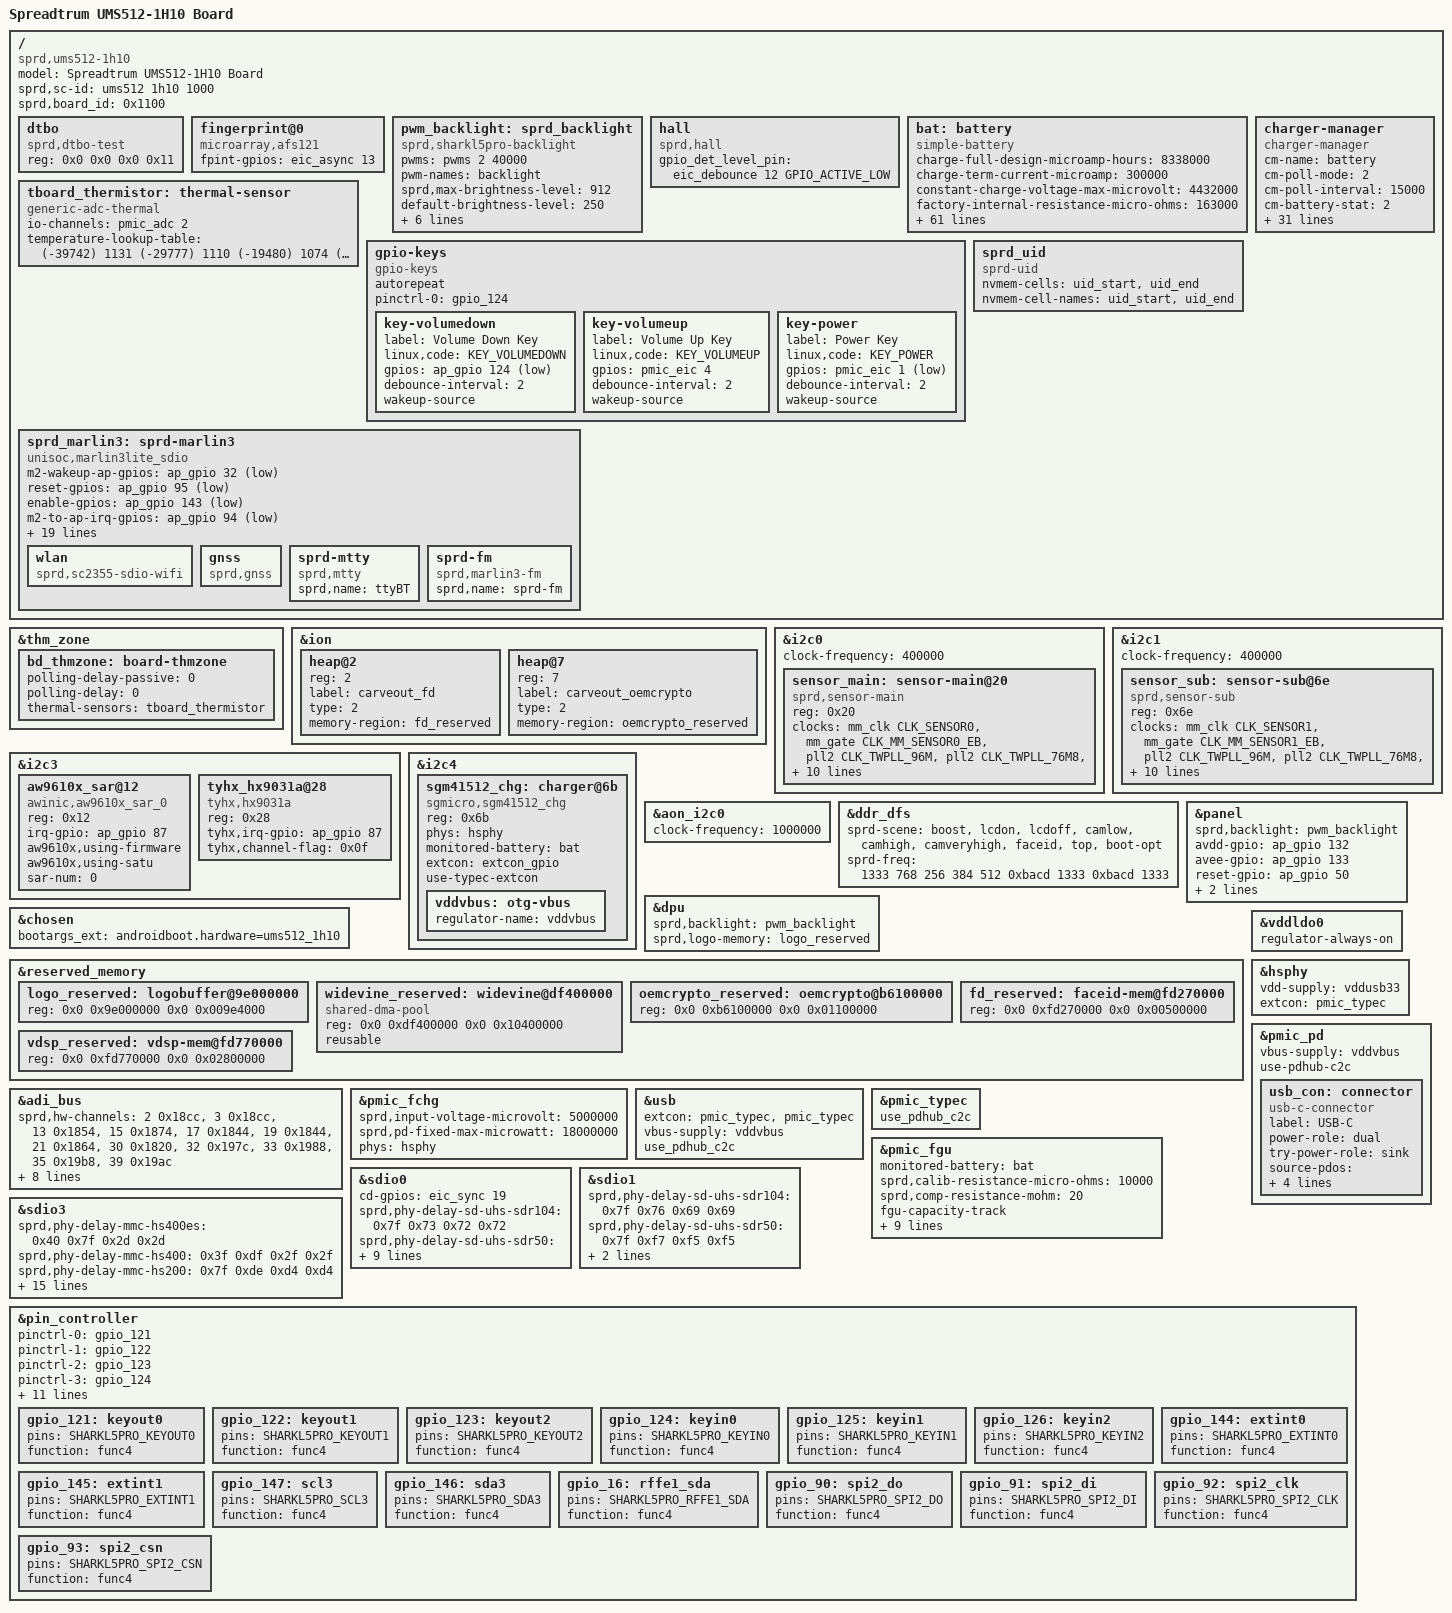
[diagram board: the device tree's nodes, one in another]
/dts-v1/;
/plugin/;

#include <dt-bindings/clock/sprd,ums512-clk.h>
#include <dt-bindings/input/input.h>
#include <dt-bindings/gpio/gpio.h>
#include <dt-bindings/mfd/sprd,sc2730-regs.h>
#include <dt-bindings/mfd/sprd,sc2730-mask.h>

#include "lcd/lcd_dijing_2A4N3_truly_mipi_fhd.dtsi"
#include "lcd/lcd_dijing_nt36523_truly_mipi_fhd.dtsi"
#include "lcd/lcd_lianchuang_mipi_fhd.dtsi"

#include "tp/novatek-nt36xxx-spi.dtsi"
#include <dt-bindings/usb/pd.h>

/ {
	model = "Spreadtrum UMS512-1H10 Board";

	compatible = "sprd,ums512-1h10", "sprd,ums512";

	sprd,sc-id = "ums512 1h10 1000";

	sprd,board_id = <0x1100>; //XX00:base board,XX00~XXFF:customize board

	fragment {
		target-path = "/";
		__overlay__ {
			#address-cells = <2>;
			#size-cells = <2>;

			dtbo: dtbo {
				compatible = "sprd,dtbo-test";
				reg = <0x0 0x0 0x0 0x11>;
			};

			fingerprint@0 {
				compatible = "microarray,afs121";
				fpint-gpios = <&eic_async 13 0>;
			};

			pwm_backlight: sprd_backlight {
				compatible = "sprd,sharkl5pro-backlight";
				pwms = <&pwms 2 40000>;
				pwm-names = "backlight";
				sprd,max-brightness-level = <912>;
				default-brightness-level = <250>;
			//	sprd,brightness-scale = <1023>;
				brightness-levels = <
						         3  11  11  11  11  12
					 12  12  12  13  13  13  14  14  15  15         //15
					 16  17  18  19  20  21  22  23  24  25        //25
					 26  27  28  29  30  31  32  33  34  35        //35
					 36  37  38  39  40  41  42  43  44  45        //45
					 46  47  48  49  52  55  58  61  64  67        //55
					 70  73  76  79  82  85  88  91  94  97         //65
					100 103 106 109 112 116 119 121 124 126        //75
					128 131 133 135 138 140 142 145 147 149			//85
					152 155 158 161 164 167 170 174 177 181			//95		 
					184 187 190 193 196 199 202 205 208 211		  // 105
					214 217 220 223 226 229 232 235 238 241		  // 115
					244 247 250 253 256 259 263 267 270 274		  // 125
					277 280 284 287 290 293 297 300 304 307		  // 135
					310 314 317 320 323 327 330 334 337 340       // 145
					344 348 352 356 360 364 363 367 371 375       // 155
					379 383 387 391 395 399 403 407 411 415	      // 165
					420 424 428 431 434 438 442 447 452 457		  // 175
					460 462 465 470 475 480 485 490 492 497       // 185
					502 507 512 517 522 527 532 537 541 547       // 195
					553 560 566 572 578 584 590 596 602 608		  // 205
					614 620 626 633 640 647 654 661 668 675       // 215
					680 685 690 705 714 724 730 742 750 756       // 225
					763 770 776 782 788 794 801 808 814 820       // 235
					826 834 841 848 854 860 867 870 874 877       // 245
					881 884 888 891 895 898 902 905 909 912
				>;
				brightness-levels-djn = <
						         0   5   5   6   6   6
					  7   8   8   9   9  10  10  11  12  13         //15
					 14  14  15  15  16  17  18  19  20  20        //25
					 21  21  22  22  23  24  24  25  25  26        //35
					 27  28  29  30  31  32  33  34  35  36        //45
					 38  40  42  43  45  47  48  49  50  52        //55
					 55  57  60  62  64  67  69  72  74  76         //65
					 78  80  82  84  86  88  90  92  94  97        //75
					 99 101 103 105 107 110 112 114 116 119			//85
					121 124 126 129 131 134 136 139 142 145			//95		 
					147 150 152 155 157 160 162 165 167 170		  // 105
					172 175 177 180 182 184 186 189 191 193		  // 115
					195 198 200 203 205 208 211 214 217 220		  // 125
					223 226 229 232 235 238 241 243 245 247		  // 135
					250 252 255 258 261 264 267 270 272 274       // 145
					277 280 283 286 289 292 295 298 301 304       // 155
					307 310 314 317 320 324 327 330 334 337	      // 165
					340 343 347 350 354 357 360 364 367 371		  // 175
					373 376 378 381 383 386 389 391 393 395       // 185
					399 404 408 413 417 422 427 432 437 442       // 195
					446 451 455 460 464 469 475 480 485 490		  // 205
					495 501 506 511 516 521 526 531 536 541       // 215
					548 555 563 570 577 585 592 599 606 614       // 225
					618 623 627 633 638 642 647 651 656 661       // 235
					665 670 677 682 687 693 698 704 709 714       // 245
					716 718 720 721 722 724 725 727 728 730
				>;
				brightness-levels-boe = <
						          0   5   6   6   7   7
					  8   9  10  10  11  11  12  12  13  13         //15
					 14  15  16  17  18  19  20  21  22  23        //25
					 24  25  26  27  28  29  30  31  32  33        //35
					 34  35  36  37  38  39  40  41  42  43        //45
					 44  45  46  47  48  49  50  51  52  53        //55
					 56  59  62  65  68  71  74  77  80  82         //65
					 85  88  90  93  96  98 101 104 106 109        //75
					111 113 115 117 118 120 122 124 126 128			//85
					131 134 137 140 141 144 147 150 152 155			//95		 
					158 160 163 166 169 172 175 177 179 181		  // 105
					184 187 190 193 196 199 202 204 206 208		  // 115
					211 214 217 220 223 226 229 221 223 235		  // 125
					238 241 244 247 250 254 257 260 263 267		  // 135
					270 273 276 279 282 285 288 291 292 293       // 145
					297 300 303 307 310 313 317 320 324 327       // 155
					330 333 337 340 343 347 350 353 357 360	      // 165
					364 368 371 374 378 381 384 388 392 395		  // 175
					399 403 407 410 414 418 422 426 430 434       // 185
					438 442 446 450 454 458 462 466 470 475       // 195
					480 486 491 497 502 508 513 519 526 532		  // 205
					538 544 550 556 562 568 574 580 585 590       // 215
					597 604 611 618 625 632 639 646 653 661       // 225
					666 671 677 682 687 692 698 703 708 714       // 235
					719 724 729 734 739 744 749 753 758 763       // 245
					765 768 770 773 775 778 780 782 785 788
				>;
			};

			hall {
				compatible = "sprd,hall";
				gpio_det_level_pin = <&eic_debounce 12 GPIO_ACTIVE_LOW>;
				status = "okay";
			};
			
			bat: battery {
				compatible = "simple-battery";
				charge-full-design-microamp-hours = <8338000>;
				charge-term-current-microamp = <300000>;
				constant-charge-voltage-max-microvolt = <4432000>;
				factory-internal-resistance-micro-ohms = <163000>;
				voltage-min-design-microvolt = <3450000>;
				fullbatt-voltage = <4340000>;
				fullbatt-current = <300000>;
				first-fullbatt-current = <150000>;
				fullbatt-track-end-vol = <4345000>;
				fullbatt-track-end-cur = <130000>;
				first-calib-voltage = <3630000>;
				first-calib-capacity = <50>;
				batt-ovp-threshold-microvolt = <4800000>;

				ocv-capacity-celsius = <20>;
				ocv-capacity-table-0 = <4353000 100>, <4288000 95>, <4229000 90>,
							<4172000 85>, <4118000 80>, <4066000 75>,
							<4014000 70>, <3973000 65>, <3927000 60>,
							<3872000 55>, <3841000 50>, <3818000 45>,
							<3799000 40>, <3783000 35>, <3770000 30>,
							<3753000 25>, <3736000 20>, <3712000 15>,
							<3685000 10>, <3668000 5>, <3400000 0>;
				voltage-temp-table = <1134000 800>, <1038000 840>, <943000 880>, <854000 920>, 
							  <771000 960>, <686000 1000>, <614000 1040>, <545000 1080>,
							  <486000 1120>, <429000 1160>, <387000 1200>, <338000 1240>,
							  <295000 1280>, <263000 1320>, <231000 1360>, <203000 1400>, 
							  <179000 1440>, <157000 1480>, <139000 1520>, <125000 1560>, 
							  <111000 1600>, <96000 1650>;
				capacity-temp-table = <45 100>, <25 100>, <10 94>, <0 94>, <(-10) 75>, <(-20) 65>;
				resistance-temp-table = <45 77>, <25 100>, <10 246>, <0 469>, <(-10) 692>, <(-20) 823>;



				charge-sdp-current-microamp = <500000 500000>;
				charge-dcp-current-microamp = <2000000 2010000>;
				charge-cdp-current-microamp = <2000000 2010000>;
				charge-unknown-current-microamp = <500000 500000>;

				cap-calib-energy-density-ocv-table = <3350000 3800000>, <4150000 4350000>;
				cap-track-energy-density-ocv-table = <3400000 3722000>;
				charge-fchg-current-microamp = <3000000 3200000>;
				dcp-jeita-temp-table = <1000 1010 0 4432000>, <1100 1110 1620000 4432000>,
					<1450 1400 2000000 4432000>, <1550 1500 2000000 4432000>;
				sdp-jeita-temp-table = <1000 1010 500000 4432000>, <1100 1110 500000 4432000>,
					<1450 1400 500000 4432000>, <1550 1500 500000 4432000>;
				cdp-jeita-temp-table = <1000 1010 1000000 4432000>, <1100 1110 1620000 4432000>,
					<1450 1400 2000000 4432000>, <1550 1500 2000000 4432000>;
				unknown-jeita-temp-table = <1000 1010 0 4432000>, <1100 1110 500000 4432000>,
					<1450 1400 500000 4432000>, <1550 1500 500000 4432000>;
                fchg-jeita-temp-table = <1000 1010 0 4432000>, <1100 1110 1620000 4432000>,
					<1450 1400 3000000 4432000>, <1550 1500 3000000 4432000>;                       
				force-jeita-status = <2>;
			};

			charger-manager {
				compatible = "charger-manager";
				cm-name = "battery";
				cm-poll-mode = <2>;
				cm-poll-interval = <15000>;
				cm-battery-stat = <2>;

				cm-fullbatt-vchkdrop-ms = <30000>;
				cm-fullbatt-vchkdrop-volt = <60000>;
				cm-fullbatt-capacity = <100>;

				cm-num-chargers = <1>;
				cm-num-fast-chargers = <1>;
				cm-chargers = "sgm41512_charger";
				sprd,support-fchg;
				cm-charge-pumps = "sc27xx_fast_charger";
				cm-fuel-gauge = "sc27xx-fgu";

				/* in deci centigrade */
				cm-battery-cold = <0>;
				cm-battery-cold-in-minus;
				cm-battery-hot = <800>;
				cm-battery-temp-diff = <100>;

				/* Allow charging for 6hr */
				cm-charging-max = <43200000>;
				/* recovery charging after stop charging 45min */
				cm-discharging-max = <2700000>;

				/* the interval to feed charger watchdog */
				cm-wdt-interval = <60>;

				/* drop voltage in microVolts to allow shutdown */
				cm-shutdown-voltage = <3400000>;

				/* when 99% of the time is exceeded, it will be forced to 100% */
				cm-tickle-time-out = <1500>;

				/* how much time to allow capacity change */
				cm-one-cap-time = <30>;
				cm-thermal-zone = "board-thmzone";
				/* when the safe charging voltage is exceeded, stop charging */
				cm-charge-voltage-max = <6500000>;
				/* drop voltage in microVolts to restart charging */
				cm-charge-voltage-drop = <700000>;
				/* when the safe charging voltage is exceeded, stop charging */
				cm-fast-charge-voltage-max = <10500000>;
				/* drop voltage in microVolts to restart charging */
				cm-fast-charge-voltage-drop = <700000>;

				monitored-battery = <&bat>;

				cm-cap-remap-table = <1 4 3>, <4 20 1>, <98 99 1>, <99 100 1>;

				phys = <&hsphy>;
				
				extcon = <&pmic_typec>, <&pmic_pd>;
				pd-extcon-enable;
				use-typec-extcon;

			};
			tboard_thermistor:thermal-sensor {
				compatible = "generic-adc-thermal";
				#thermal-sensor-cells = <0>;
				io-channels = <&pmic_adc 2>;
				io-channel-names = "sensor-channel";
				temperature-lookup-table = <    (-39742) 1131
								(-29777) 1110
								(-19480) 1074
								(-4679) 983
								10110 838
								24805 654
								44922 413
								54903 316
								64895 238
								74884 178
								84883 133
								94883 100
								104880 75
								114889 57
								124872 43 >;
			};
			gpio-keys {
				compatible = "gpio-keys";
				autorepeat;
				pinctrl-names = "gpio_124";
				pinctrl-0 = <&gpio_124>;
				key-volumedown {
					label = "Volume Down Key";
					linux,code = <KEY_VOLUMEDOWN>;
					gpios = <&ap_gpio 124 GPIO_ACTIVE_LOW>;
					debounce-interval = <2>;
					wakeup-source;
				};

				key-volumeup {
					label = "Volume Up Key";
					linux,code = <KEY_VOLUMEUP>;
					gpios = <&pmic_eic 4 GPIO_ACTIVE_HIGH>;
					debounce-interval = <2>;
					wakeup-source;
				};

				key-power {
					label = "Power Key";
					linux,code = <KEY_POWER>;
					gpios = <&pmic_eic 1 GPIO_ACTIVE_LOW>;
					debounce-interval = <2>;
					wakeup-source;
				};
			};

			sprd_uid {
				compatible = "sprd-uid";
				nvmem-cells = <&uid_start>, <&uid_end>;
				nvmem-cell-names = "uid_start", "uid_end";
			};

			sprd_marlin3: sprd-marlin3 {
				compatible = "unisoc,marlin3lite_sdio";
				m2-wakeup-ap-gpios = <&ap_gpio 32 GPIO_ACTIVE_LOW>;
				reset-gpios = <&ap_gpio 95 GPIO_ACTIVE_LOW>;
				enable-gpios = <&ap_gpio 143 GPIO_ACTIVE_LOW>;
				m2-to-ap-irq-gpios = <&ap_gpio 94 GPIO_ACTIVE_LOW>;
				avdd12-supply = <&vddwcn>;
				avdd33-supply = <&vddwifipa>;
				dcxo18-supply = <&vddsim2>;

				clock-names = "clk_32k","source","enable";
				clocks = <&aon_clk CLK_AUX0>,
					 <&ext_32k>,
					 <&aonapb_gate CLK_AUX0_EB>;

				extcon = <&sdio1>;
				sdhci-name = <&sdio1>;

				sprd,btwf-file-name = "/dev/block/platform/soc/soc:ap-apb/71400000.sdio/by-name/wcnmodem";
				sprd,gnss-file-name = "/vendor/firmware/gnssmodem.bin";
				adma-tx;
				adma-rx;
				/*
				 * bound parameter:
				 * [0]:addr offset, [1]:mask, [2]:unboundval, [3]:boundval
				 */
				avdd12-parent-bound-chip = <REG_ANA_SLP_DCDC_PD_CTRL MASK_ANA_SLP_DCDCGEN1_PD_EN 0x0 MASK_ANA_SLP_DCDCGEN1_PD_EN>;
				avdd12-bound-wbreq = <REG_ANA_LDO_XTL_EN10 MASK_ANA_LDO_VDDWCN_EXT_XTL3_EN 0x0 MASK_ANA_LDO_VDDWCN_EXT_XTL3_EN>;
				avdd33-bound-wbreq = <REG_ANA_LDO_XTL_EN11 MASK_ANA_LDO_VDDWIFIPA_EXT_XTL3_EN 0x0 MASK_ANA_LDO_VDDWIFIPA_EXT_XTL3_EN>;

				wlan {
					compatible = "sprd,sc2355-sdio-wifi";
				};

				gnss {
					compatible = "sprd,gnss";
				};

				sprd-mtty {
					compatible = "sprd,mtty";
					sprd,name = "ttyBT";
				};

				sprd-fm {
					compatible = "sprd,marlin3-fm";
					sprd,name = "sprd-fm";
				};
			};
		};
	};
};

&thm_zone {
	bd_thmzone: board-thmzone {
		polling-delay-passive = <0>;
		polling-delay = <0>;
		thermal-sensors = <&tboard_thermistor>;
	};
};

&ion {
	#address-cells = <1>;
	#size-cells = <0>;

	heap@2 {
		reg = <2>;
		label = "carveout_fd";
		type = <2>;
		memory-region = <&fd_reserved>;
	};

	heap@7 {
		reg = <7>;
		label = "carveout_oemcrypto";
		type = <2>;
		memory-region = <&oemcrypto_reserved>;
	};
};

&i2c0 {
	#address-cells = <1>;
	#size-cells = <0>;

	status = "okay";
	clock-frequency = <400000>;

	sensor_main: sensor-main@20 {
		compatible = "sprd,sensor-main";
		reg = <0x20>;
		clock-names = "clk_src","sensor_eb",
			"clk_96m","clk_76m8",
			"clk_48m","clk_26m";
		clocks = <&mm_clk CLK_SENSOR0>,<&mm_gate CLK_MM_SENSOR0_EB>,
				<&pll2 CLK_TWPLL_96M>,<&pll2 CLK_TWPLL_76M8>,
				<&pll2 CLK_TWPLL_48M>,<&ext_26m>;
		vddio-supply = <&vddcamio>;
		vddcama-supply = <&vddcama0>;
		vddcamd-supply = <&vddcamd0>;
		vddcammot-supply = <&vddcammot>;
		reset-gpios = <&ap_gpio 44 0>;
		power-down-gpios = <&ap_gpio 46 0>;
		sprd,phyid = <0>;
		csi = <&csi0>;
		power-domains = <&mm_domain>;
	};

/*	sensor_sub: sensor-sub@5a {
		compatible = "sprd,sensor-sub";
		reg = <0x5a>;
		clock-names = "clk_src","sensor_eb",
			"clk_96m","clk_76m8",
			"clk_48m","clk_26m";
		clocks = <&mm_clk CLK_SENSOR0>,<&mm_gate CLK_MM_SENSOR0_EB>,
				<&pll2 CLK_TWPLL_96M>,<&pll2 CLK_TWPLL_76M8>,
				<&pll2 CLK_TWPLL_48M>,<&ext_26m>;
		vddio-supply = <&vddcamio>;
		vddcama-supply = <&vddcama0>;
		vddcamd-supply = <&vddcamd0>;
		vddcammot-supply = <&vddcammot>;
		reset-gpios = <&ap_gpio 41 0>;
		power-down-gpios = <&ap_gpio 40 0>;
		mipi-switch-en-gpios = <&ap_gpio 55 0>;
		mipi-switch-mode-gpios = <&ap_gpio 8 0>;
		sprd,phyid = <1>;
		csi = <&csi1>;
		power-domains = <&mm_domain>;
	};*/
};

&i2c1 {
	#address-cells = <1>;
	#size-cells = <0>;

	status = "okay";
	clock-frequency = <400000>;

/*	sensor_main2: sensor-main2@20 {
		compatible = "sprd,sensor-main2";
		reg = <0x20>;
		clock-names = "clk_src","sensor_eb",
			"clk_96m","clk_76m8",
			"clk_48m","clk_26m";
		clocks = <&mm_clk CLK_SENSOR1>,<&mm_gate CLK_MM_SENSOR1_EB>,
				<&pll2 CLK_TWPLL_96M>,<&pll2 CLK_TWPLL_76M8>,
				<&pll2 CLK_TWPLL_48M>,<&ext_26m>;
		vddio-supply = <&vddcamio>;
		vddcama-supply = <&vddcama1>;
		vddcamd-supply = <&vddcamd1>;
		vddcammot-supply = <&vddcammot>;
		avdd-gpios = <&ap_gpio 33 0>;
		mot-gpios = <&ap_gpio 88 0>;
		reset-gpios = <&ap_gpio 45 0>;
		power-down-gpios = <&ap_gpio 47 0>;
		mipi-switch-en-gpios = <&ap_gpio 55 0>;
		mipi-switch-mode-gpios = <&ap_gpio 8 0>;
		sprd,phyid = <1>;
		csi = <&csi1>;
		power-domains = <&mm_domain>;
	};*/

	sensor_sub: sensor-sub@6e {
		compatible = "sprd,sensor-sub";
		reg = <0x6e>;
		clock-names = "clk_src","sensor_eb",
			"clk_96m","clk_76m8",
			"clk_48m","clk_26m";
		clocks = <&mm_clk CLK_SENSOR1>,<&mm_gate CLK_MM_SENSOR1_EB>,
			<&pll2 CLK_TWPLL_96M>,<&pll2 CLK_TWPLL_76M8>,
			<&pll2 CLK_TWPLL_48M>,<&ext_26m>;
		vddio-supply = <&vddcamio>;
		vddcama-supply = <&vddcama0>;
		vddcamd-supply = <&vddcamd0>;
		vddcammot-supply = <&vddcammot>;
	//	mot-gpios = <&ap_gpio 88 0>;
		reset-gpios = <&ap_gpio 45 0>;
		power-down-gpios = <&ap_gpio 47 0>;
		sprd,phyid = <3>;
		csi = <&csi1>;
		power-domains = <&mm_domain>;
	};

/*	sensor_main3: sensor-main3@6c {
		compatible = "sprd,sensor-main3";
		reg = <0x6c>;
		clock-names = "clk_src","sensor_eb",
			"clk_96m","clk_76m8",
			"clk_48m","clk_26m";
		clocks = <&mm_clk CLK_SENSOR1>,<&mm_gate CLK_MM_SENSOR1_EB>,
				<&pll2 CLK_TWPLL_96M>,<&pll2 CLK_TWPLL_76M8>,
				<&pll2 CLK_TWPLL_48M>,<&ext_26m>;
		vddio-supply = <&vddcamio>;
		vddcama-supply = <&vddcama1>;
		vddcamd-supply = <&vddcamd1>;
		vddcammot-supply = <&vddcammot>;
		mot-gpios = <&ap_gpio 88 0>;
		reset-gpios = <&ap_gpio 41 0>;
		power-down-gpios = <&ap_gpio 40 0>;
		sprd,phyid = <2>;
		csi = <&csi2>;
		power-domains = <&mm_domain>;
	};*/
};

&i2c3 {
	#address-cells = <1>;
	#size-cells = <0>;

	status = "okay";

	aw9610x_sar@12 {
		compatible = "awinic,aw9610x_sar_0";
		reg = <0x12>;
		irq-gpio = <&ap_gpio 87 0>;
		aw9610x,using-firmware;
		aw9610x,using-satu;
		sar-num = <0>;
		status = "okay";
	};
	
	tyhx_hx9031a@28 {
		compatible = "tyhx,hx9031a";
		reg = <0x28>;
		tyhx,irq-gpio = <&ap_gpio 87 0>;
		tyhx,channel-flag = <0x0f>; 
	};

};

&i2c4 {
	#address-cells = <1>;
	#size-cells = <0>;

	sgm41512_chg: charger@6b {
		compatible = "sgmicro,sgm41512_chg";
		reg = <0x6b>;
		phys = <&hsphy>;
		monitored-battery = <&bat>;
		extcon = <&extcon_gpio>;
		use-typec-extcon;
		vddvbus:otg-vbus {
			regulator-name = "vddvbus";
		};
	};
};

&aon_i2c0 {
	status = "okay";
	clock-frequency = <1000000>;
};

&ddr_dfs {
	sprd-scene = "boost", "lcdon", "lcdoff", "camlow",
		"camhigh", "camveryhigh", "faceid", "top", "boot-opt";
	sprd-freq = <1333 768 256 384 512 0xbacd 1333 0xbacd 1333>;
};

&panel {
	sprd,backlight = <&pwm_backlight>;
	avdd-gpio = <&ap_gpio 132 GPIO_ACTIVE_HIGH>;
	avee-gpio = <&ap_gpio 133 GPIO_ACTIVE_HIGH>;
	reset-gpio = <&ap_gpio 50 GPIO_ACTIVE_HIGH>;
	tp3v3en-gpio = <&ap_gpio 156 GPIO_ACTIVE_HIGH>;
	lcm1v8en-gpio = <&ap_gpio 136 GPIO_ACTIVE_HIGH>;
};

&dpu {
	sprd,backlight = <&pwm_backlight>;
	sprd,logo-memory = <&logo_reserved>;
};

&chosen {
	bootargs_ext = "androidboot.hardware=ums512_1h10";
};

&reserved_memory {
	#address-cells = <2>;
	#size-cells = <2>;

	logo_reserved: logobuffer@9e000000{
		reg = <0x0 0x9e000000 0x0 0x009e4000>;
	};

	/*Set 8M after widevine to prevent memory out of bounds*/
	widevine_reserved: widevine@df400000 {
		compatible = "shared-dma-pool";
		reg = <0x0 0xdf400000 0x0 0x10400000>;
		reusable;
	};
	/* Encrypt and decrypt widevine video */
	oemcrypto_reserved: oemcrypto@b6100000 {
		reg = <0x0 0xb6100000 0x0 0x01100000>;
	};

	fd_reserved: faceid-mem@fd270000 {
		reg = <0x0 0xfd270000 0x0 0x00500000>;
	};

	vdsp_reserved: vdsp-mem@fd770000 {
		reg = <0x0 0xfd770000 0x0 0x02800000>;
	};
};

&adi_bus {
	sprd,hw-channels = <2 0x18cc>, <3 0x18cc>, <13 0x1854>, <15 0x1874>,
			   <17 0x1844>, <19 0x1844>, <21 0x1864>, <30 0x1820>,
			   <32 0x197c>, <33 0x1988>, <35 0x19b8>, <39 0x19ac>;
	sprd,hw-channels0 = <2 0x18cc>, <3 0x18cc>, <13 0x1874>, <15 0x1874>,
			<17 0x1844>, <19 0x1854>, <21 0x1864>, <30 0x1820>,
			<32 0x197c>, <33 0x1988>, <35 0x19b8>, <39 0x19ac>;
	sprd,hw-channels1 = <2 0x18cc>, <3 0x18cc>, <13 0x1854>, <15 0x1874>,
			<17 0x1844>, <19 0x1844>, <21 0x1864>, <30 0x1820>,
			<35 0x19b8>, <39 0x19ac>, <32 0x197c>, <33 0x1988>;
};

&vddldo0 {
	regulator-always-on;
};

&hsphy {
	vdd-supply = <&vddusb33>;
	extcon = <&pmic_typec>;
	status = "okay";
};

&pmic_fchg {
        status = "okay";
        sprd,input-voltage-microvolt = <5000000>;
        sprd,pd-fixed-max-microwatt = <18000000>;
        //sprd,support-sfcp;
        //sprd,support-pd-pps;
        phys = <&hsphy>;

};

&pmic_pd {
		status = "okay";
		vbus-supply = <&vddvbus>;
		use-pdhub-c2c;
		usb_con: connector {
			compatible = "usb-c-connector";
			label = "USB-C";
			power-role = "dual";
			try-power-role = "sink";
			source-pdos = <PDO_FIXED(5000, 400, PDO_FIXED_USB_COMM |
					PDO_FIXED_DUAL_ROLE | PDO_FIXED_DATA_SWAP)>;
			sink-pdos = <PDO_FIXED(5000, 3000, PDO_FIXED_USB_COMM)>;
			op-sink-microwatt = <10000000>;
		};
};


&usb {
	extcon = <&pmic_typec>, <&pmic_typec>;
	status = "okay";
	vbus-supply = <&vddvbus>;
	use_pdhub_c2c;
};

&pmic_typec {
	use_pdhub_c2c;
};

&pmic_fgu {
	monitored-battery = <&bat>;
	sprd,calib-resistance-micro-ohms = <10000>;
	sprd,comp-resistance-mohm = <20>;

	fgu-capacity-track;
	phys = <&hsphy>;

	sprd,relax-counter-threshold = <580>;
	sprd,relax-current-threshold = <30>;
	sprd,capacity-sleep-calibration;

	sprd,capacity-boot-calibration;
	sprd,capacity-charge-cycle;
	sprd,basp;
	use-typec-extcon;
	extcon = <&pmic_typec>;
};

&sdio0 {
	cd-gpios = <&eic_sync 19 GPIO_ACTIVE_HIGH>;
	sprd,phy-delay-sd-uhs-sdr104 = <0x7f 0x73 0x72 0x72>;
	sprd,phy-delay-sd-uhs-sdr50 = <0x6e 0x7f 0x01 0x01>;
	sprd,phy-delay-sd-highspeed = <0x7f 0x1a 0x9a 0x9a>;
	sprd,phy-delay-legacy = <0x7f 0x1a 0x9a 0x9a>;
	vmmc-supply = <&vddsdcore>;
	vqmmc-supply = <&vddsdio>;
	sd-uhs-sdr104;
	sd-uhs-sdr50;
	sprd,name = "sdio_sd";
	status = "okay";
};

&sdio1 {
	sprd,phy-delay-sd-uhs-sdr104 = <0x7f 0x76 0x69 0x69>;
	sprd,phy-delay-sd-uhs-sdr50 = <0x7f 0xf7 0xf5 0xf5>;
	sd-uhs-sdr104;
	sd-uhs-sdr50;
};

&sdio3 {
	sprd,phy-delay-mmc-hs400es = <0x40 0x7f 0x2d 0x2d>;
	sprd,phy-delay-mmc-hs400 = <0x3f 0xdf 0x2f 0x2f>;
	sprd,phy-delay-mmc-hs200 = <0x7f 0xde 0xd4 0xd4>;
	sprd,phy-delay-mmc-ddr52 = <0x3e 0x37 0x24 0x24>;
	sprd,phy-delay-mmc-highspeed = <0x60 0xb7 0x34 0x34>;
	vmmc-supply = <&vddemmccore>;
	voltage-ranges = <3000 3000>;
	bus-width = <8>;
	non-removable;
	cap-mmc-hw-reset;
	mmc-hs400-enhanced-strobe;
	mmc-hs400-1_8v;
	mmc-hs200-1_8v;
	mmc-ddr-1_8v;
	sprd,name = "sdio_emmc";
	no-sdio;
	no-sd;
	status = "okay";
};

&pin_controller {
	pinctrl-names =
	/* keyout0 ~ keyout2 */
	"gpio_121", "gpio_122", "gpio_123",
	/* keyin0 ~ keyin2 */
	"gpio_124", "gpio_125", "gpio_126",
	/* extint0, extint1, scl3, sda3, sda */
	"gpio_144", "gpio_145", "gpio_146", "gpio_147", "gpio_16",
	"gpio_90", "gpio_91", "gpio_92", "gpio_93";

	pinctrl-0 = <&gpio_121>;
	pinctrl-1 = <&gpio_122>;
	pinctrl-2 = <&gpio_123>;
	pinctrl-3 = <&gpio_124>;
	pinctrl-4 = <&gpio_125>;
	pinctrl-5 = <&gpio_126>;
	pinctrl-6 = <&gpio_144>;
	pinctrl-7 = <&gpio_145>;
	pinctrl-8 = <&gpio_146>;
	pinctrl-9 = <&gpio_147>;
	pinctrl-10 = <&gpio_16>;
    pinctrl-11 = <&gpio_90>;
    pinctrl-12 = <&gpio_91>;
    pinctrl-13 = <&gpio_92>;
    pinctrl-14 = <&gpio_93>;
	
	gpio_121: keyout0 {
		pins = "SHARKL5PRO_KEYOUT0";
		function = "func4";
	};

	gpio_122: keyout1 {
		pins = "SHARKL5PRO_KEYOUT1";
		function = "func4";
	};

	gpio_123: keyout2 {
		pins = "SHARKL5PRO_KEYOUT2";
		function = "func4";
	};

	gpio_124: keyin0 {
		pins = "SHARKL5PRO_KEYIN0";
		function = "func4";
	};

	gpio_125: keyin1 {
		pins = "SHARKL5PRO_KEYIN1";
		function = "func4";
	};

	gpio_126: keyin2 {
		pins = "SHARKL5PRO_KEYIN2";
		function = "func4";
	};

	gpio_144: extint0 {
		pins = "SHARKL5PRO_EXTINT0";
		function = "func4";
	};

	gpio_145: extint1 {
		pins = "SHARKL5PRO_EXTINT1";
		function = "func4";
	};

	gpio_147: scl3 {
		pins = "SHARKL5PRO_SCL3";
		function = "func4";
	};

	gpio_146: sda3 {
		pins = "SHARKL5PRO_SDA3";
		function = "func4";
	};

	gpio_16: rffe1_sda {
		pins = "SHARKL5PRO_RFFE1_SDA";
		function = "func4";
	};
     gpio_90: spi2_do {
         pins = "SHARKL5PRO_SPI2_DO";
         function = "func4";
     };
 
     gpio_91: spi2_di {
         pins = "SHARKL5PRO_SPI2_DI";
         function = "func4";
     };
 
     gpio_92: spi2_clk {
         pins = "SHARKL5PRO_SPI2_CLK";
         function = "func4";
     };
 
     gpio_93: spi2_csn {
         pins = "SHARKL5PRO_SPI2_CSN";
         function = "func4";
     };
};
